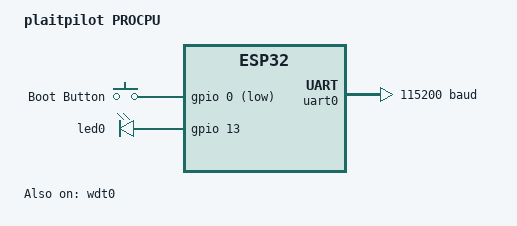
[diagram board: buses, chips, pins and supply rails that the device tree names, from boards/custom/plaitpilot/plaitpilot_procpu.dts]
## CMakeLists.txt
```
cmake_minimum_required(VERSION 3.22)

project(app)
find_package(Zephyr REQUIRED HINTS $ENV{ZEPHYR_BASE})

# this didn't work when this was called app. It must be called app because... TO-DO
target_sources(app PRIVATE src/main.c)
```

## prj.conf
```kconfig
# doesnt need anything because we are using the default configuration from the board
```

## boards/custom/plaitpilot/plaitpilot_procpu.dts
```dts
/dts-v1/;

#include "espressif/esp32/esp32_wroom_32ue_n4.dtsi"
#include "plaitpilot_pinctrl.dtsi"
// this is standard input codes like for a keyboard, mouse, joystick etc. - the purpose is for convenience
// you can always use these zephyr specific input macros in source code as long as you define them in this dts file, this way only the dts file changes and the source code does not
#include <zephyr/dt-bindings/input/input-event-codes.h>
// this is the SoC configuration (partitions like boot, appcpu, procpu, sys, storage, coredump)
#include <espressif/partitions_0x0_amp.dtsi>

/ {
    model = "plaitpilot PROCPU";
    compatible = "custom,plaitpilot";

    aliases {
        //driver code uses this to keep procesors alive during code execution
        watchdog0 = &wdt0;
        // this is an LED that is "permenantly" soldered on the board
        led-0 = &led0;
        uart-0 = &uart0;
        sw0 = &button0;
    };

    // this determines which hardware instances you want to use for core system level functions
    chosen {
        zephyr,sram = &sram0;
        zephyr,console = &uart0;
        zephyr,shell-uart = &uart0;
        zephyr,flash = &flash0;
        zephyr,code-partition = &slot0_partition;
    };

    buttons {
        compatible = "gpio-keys";
        button0: button_0 {
            gpios = <&gpio 0 (GPIO_PULL_UP | GPIO_ACTIVE_LOW)>;
            label = "Boot Button";
            zephyr,code = <INPUT_KEY_0>;
        };
    };

    led {
        compatible = "gpio-leds";
        // this is SPI MOSI for plaitpliot, this is just for a blinky demo
        led0: d13 {
            gpios = <&gpio 13 GPIO_ACTIVE_HIGH>;
        };
    };
};

&cpu0 {
    clock-frequency = <240000000>;
    xtal-freq = <40000000>;  // 40MHz crystal
};

// &cpu1 {
//     clock-frequency = <DT_FREQ_M(240)>;
// };

&uart0 {
    status = "okay";
    current-speed = <115200>;
    pinctrl-0 = <&uart0_default>;
    pinctrl-names = "default";
};

&gpio {
    status = "okay";
};

&wdt0 {
    status = "okay";
};
```

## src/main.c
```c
#include <zephyr/kernel.h>
#include <zephyr/device.h>
#include <zephyr/drivers/gpio.h>

static const struct device *gpio_ct_dev=
	DEVICE_DT_GET(DT_NODELABEL(gpio0));

int main(void)
{
    if(!device_is_ready(gpio_ct_dev))
    {
        return 0;
    }

    int ret;
    ret= gpio_pin_configure(gpio_ct_dev, 25, GPIO_OUTPUT_ACTIVE);

    if(ret!=0)
    {
        return 0;
    }

    while(true)
    {
        ret = gpio_pin_set_raw(gpio_ct_dev,25,1);
        if(ret!=0)
        {
            return 0;
        }
        k_msleep(500);

        ret = gpio_pin_set_raw(gpio_ct_dev,25,0);
        if(ret!=0)
        {
            return 0;
        }
        k_msleep(500);

    }

    return 1;
}
```

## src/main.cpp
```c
#include <zephyr/kernel.h>
#include <zephyr/device.h>
#include <zephyr/drivers/gpio.h>

static const struct device *gpio_ct_dev=
	DEVICE_DT_GET(DT_NODELABEL(gpio0));

void main(void)
{
if(!device_is_ready(gpio_ct_dev))
{
return;
}

int ret;
ret= gpio_pin_configure(gpio_ct_dev, 25, GPIO_OUTPUT_ACTIVE);

if(ret!=0)
{
return;
}
while(true)
{
ret = gpio_pin_set_raw(gpio_ct_dev,25,1);
if(ret!=0)
{
return;
}
k_msleep(500);

ret = gpio_pin_set_raw(gpio_ct_dev,25,0);
if(ret!=0)
{
return;
}
k_msleep(500);

}
}
```
